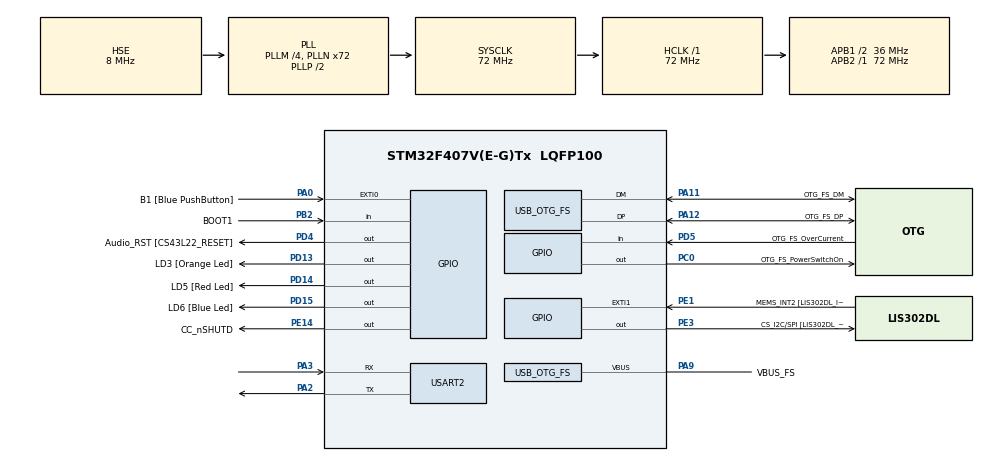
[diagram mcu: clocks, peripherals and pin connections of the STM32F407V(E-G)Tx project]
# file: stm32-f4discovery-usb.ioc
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Mcu.Family=STM32F4
PA11.GPIO_Speed=GPIO_SPEED_FREQ_LOW
PC3.GPIO_Mode=GPIO_MODE_AF_PP
PH0-OSC_IN.Signal=RCC_OSC_IN
RCC.CortexFreq_Value=72000000
PC10.GPIO_PuPd=GPIO_NOPULL
PB10.GPIO_Speed=GPIO_SPEED_FREQ_LOW
PB6.GPIO_Mode=GPIO_MODE_AF_OD
PB10.GPIO_PuPd=GPIO_NOPULL
PA10.GPIO_PuPd=GPIO_NOPULL
PD15.GPIO_Speed=GPIO_SPEED_FREQ_LOW
PC10.Signal=I2S3_CK
PC12.Signal=I2S3_SD
PA14.GPIO_Label=SWCLK
PA7.GPIO_Mode=GPIO_MODE_AF_PP
PC0.GPIO_Label=OTG_FS_PowerSwitchOn
PA11.Mode=Host_Only
PA6.GPIO_Label=SPI1_MISO [LIS302DL_SDO]
PB6.GPIO_Label=Audio_SCL [CS43L22_SCL]
PC10.GPIO_Speed=GPIO_SPEED_FREQ_LOW
PA11.GPIO_PuPd=GPIO_NOPULL
VP_USB_HOST_VS_USB_HOST_HID_FS.Mode=HID_FS
PC15-OSC32_OUT.GPIO_Label=PC15-OSC32_OUT
PC3.GPIO_Speed=GPIO_SPEED_FREQ_LOW
RCC.SYSCLKSource=RCC_SYSCLKSOURCE_PLLCLK
ProjectManager.StackSize=0x400
PA6.GPIO_Mode=GPIO_MODE_AF_PP
PD13.Signal=GPIO_Output
PD14.GPIO_Speed=GPIO_SPEED_FREQ_LOW
PA12.Signal=USB_OTG_FS_DP
RCC.HCLKFreq_Value=72000000
PD4.Signal=GPIO_Output
RCC.APB2TimFreq_Value=72000000
PB6.Signal=I2C1_SCL
PC7.Signal=I2S3_MCK
PC3.Signal=I2S2_SD
PE1.Signal=GPXTI1
USB_HOST0.BSP.ip=GPIO
RCC.AHBFreq_Value=72000000
PH0-OSC_IN.Mode=HSE-External-Oscillator
PH0-OSC_IN.GPIO_Label=PH0-OSC_IN
PA9.GPIO_Mode=GPIO_MODE_INPUT
RCC.HSE_VALUE=8000000
USB_OTG_FS.phy_itface=HCD_PHY_EMBEDDED
PA4.GPIO_PuPd=GPIO_NOPULL
PB2.Signal=GPIO_Input
PA4.GPIO_Speed=GPIO_SPEED_FREQ_LOW
PA6.GPIO_PuPd=GPIO_NOPULL
PA5.GPIO_PuPd=GPIO_NOPULL
USB_HOST.USBH_HandleTypeDef-HID_FS=hUsbHostFS
PA10.GPIO_Label=OTG_FS_ID
PC7.GPIO_Mode=GPIO_MODE_AF_PP
PD5.GPIO_Mode=GPIO_MODE_INPUT
PD14.GPIO_PuPd=GPIO_NOPULL
PB2.GPIO_PuPd=GPIO_NOPULL
PH1-OSC_OUT.Mode=HSE-External-Oscillator
USB_HOST0.BSP.i2caddr=0
PD13.GPIO_Label=LD3 [Orange Led]
Mcu.Package=LQFP100
PB9.Signal=I2C1_SDA
PA6.Signal=SPI1_MISO
USART2.VirtualMode=VM_ASYNC
PD12.Signal=USART3_RTS
PD5.GPIO_Label=OTG_FS_OverCurrent
NVIC.OTG_FS_IRQn=true\:0\:0\:false\:false\:true\:false\:true
PD15.GPIO_PuPd=GPIO_NOPULL
PA10.Signal=USB_OTG_FS_ID
PB9.GPIO_PuPd=GPIO_NOPULL
USB_OTG_FS.VirtualMode=Host_Only
PA10.GPIO_Speed=GPIO_SPEED_FREQ_LOW
USB_HOST0.BSP.name=Drive_VBUS_FS
PB9.GPIO_Speed=GPIO_SPEED_FREQ_LOW
RCC.APB1TimFreq_Value=72000000
PC14-OSC32_IN.GPIO_Label=PC14-OSC32_IN
PC12.GPIO_PuPd=GPIO_NOPULL
PA6.GPIO_Speed=GPIO_SPEED_FREQ_LOW
PC0.GPIO_PuPd=GPIO_NOPULL
PA12.GPIO_PuPd=GPIO_NOPULL
PA4.GPIO_Label=I2S3_WS [CS43L22_LRCK]
PD15.Signal=GPIO_Output
PA12.GPIO_Speed=GPIO_SPEED_FREQ_LOW
PA3.Signal=USART2_RX
PB3.GPIO_Label=SWO
PD15.GPIO_Label=LD6 [Blue Led]
PB9.GPIO_Label=Audio_SDA [CS43L22_SDA]
PC10.GPIO_Label=I2S3_SCK [CS43L22_SCLK]
PA9.GPIO_Label=VBUS_FS
PB6.GPIO_PuPd=GPIO_NOPULL
USB_HOST0.BSP.solution=PC0
USB_HOST.BSP.number=1
PA11.GPIO_Label=OTG_FS_DM
PE14.GPIO_Label=CC_nSHUTD
PE1.GPIO_PuPd=GPIO_NOPULL
PD9.Signal=USART3_RX
PD5.Signal=GPIO_Input
PC0.Signal=GPIO_Output
PE1.GPIO_ModeDefaultEXTI=GPIO_MODE_EVT_RISING
RCC.APB1CLKDivider=RCC_HCLK_DIV2
PC14-OSC32_IN.Signal=RCC_OSC32_IN
PA9.GPIO_PuPd=GPIO_NOPULL
NVIC.USART2_IRQn=true\:15\:0\:true\:false\:true\:true\:true
PA0-WKUP.GPIO_ModeDefaultEXTI=GPIO_MODE_EVT_RISING
PA12.GPIO_Label=OTG_FS_DP
PA0-WKUP.GPIO_Label=B1 [Blue PushButton]
PA0-WKUP.Signal=GPXTI0
PA10.GPIO_Mode=GPIO_MODE_AF_PP
USB_HOST0.BSP.STBoard=false
PA3.Mode=Asynchronous
PA13.Signal=SYS_JTMS-SWDIO
PC10.GPIO_Mode=GPIO_MODE_AF_PP
PD4.GPIO_PuPd=GPIO_NOPULL
PA9.Mode=Activate_VBUS
PC0.GPIO_Speed=GPIO_SPEED_FREQ_LOW
PB10.GPIO_Mode=GPIO_MODE_AF_PP
ProjectManager.TargetToolchain=Makefile
PB10.GPIO_Label=CLK_IN [MP45DT02_CLK]
PA9.Signal=USB_OTG_FS_VBUS
PC7.GPIO_PuPd=GPIO_NOPULL
RCC.LSE_VALUE=32768
PC15-OSC32_OUT.Signal=RCC_OSC32_OUT
PA7.GPIO_PuPd=GPIO_NOPULL
PB10.Signal=I2S2_CK
PA5.Signal=SPI1_SCK
board=STM32F4DISCOVERY
PD13.GPIO_Speed=GPIO_SPEED_FREQ_LOW
PC7.GPIO_Speed=GPIO_SPEED_FREQ_LOW
RCC.VCOOutputFreq_Value=144000000
PE1.GPIO_Label=MEMS_INT2 [LIS302DL_INT2]
USB_HOST.VirtualModeFS=Hid
PA7.GPIO_Speed=GPIO_SPEED_FREQ_LOW
PB9.GPIO_Mode=GPIO_MODE_AF_OD
PA12.GPIO_Mode=GPIO_MODE_AF_PP
PA4.GPIO_Mode=GPIO_MODE_AF_PP
RCC.APB2Freq_Value=72000000
USB_HOST0.BSP.api=Unknown
PB2.GPIO_Mode=GPIO_MODE_INPUT
PE14.Signal=GPIO_Output
PD4.GPIO_Label=Audio_RST [CS43L22_RESET]
PD4.GPIO_Speed=GPIO_SPEED_FREQ_LOW
PE3.GPIO_PuPd=GPIO_NOPULL
PH1-OSC_OUT.Signal=RCC_OSC_OUT
PD13.GPIO_PuPd=GPIO_NOPULL
PD5.GPIO_PuPd=GPIO_NOPULL
PD14.GPIO_Label=LD5 [Red Led]
PH1-OSC_OUT.GPIO_Label=PH1-OSC_OUT
Mcu.Name=STM32F407V(E-G)Tx
PA2.Signal=USART2_TX
PA13.GPIO_Label=SWDIO
PC7.GPIO_Label=I2S3_MCK [CS43L22_MCLK]
PD14.Signal=GPIO_Output
RCC.48MHZClocksFreq_Value=48000000
PB3.Signal=SYS_JTDO-SWO
PA4.Signal=I2S3_WS
RCC.SYSCLKFreq_VALUE=72000000
PC12.GPIO_Mode=GPIO_MODE_AF_PP
PA7.GPIO_Label=SPI1_MOSI [LIS302DL_SDA/SDI/SDO]
PA12.Mode=Host_Only
PA5.GPIO_Label=SPI1_SCK [LIS302DL_SCL/SPC]
PE3.GPIO_Speed=GPIO_SPEED_FREQ_LOW
PD11.Signal=USART3_CTS
PC12.GPIO_Label=I2S3_SD [CS43L22_SDIN]
PA11.Signal=USB_OTG_FS_DM
PA14.Signal=SYS_JTCK-SWCLK
PB2.GPIO_Label=BOOT1
ProjectManager.HeapSize=0x200
RCC.HSI_VALUE=16000000
PA5.GPIO_Speed=GPIO_SPEED_FREQ_LOW
RCC.PLLQ=3
NVIC.PriorityGroup=NVIC_PRIORITYGROUP_4
RCC.PLLM=4
RCC.PLLN=72
PE3.Signal=GPIO_Output
PA2.Mode=Asynchronous
PE3.GPIO_Label=CS_I2C/SPI [LIS302DL_CS_I2C/SPI]
PC3.GPIO_Label=PDM_OUT [MP45DT02_DOUT]
PA0-WKUP.GPIO_PuPd=GPIO_NOPULL
PA11.GPIO_Mode=GPIO_MODE_AF_PP
PB6.GPIO_Speed=GPIO_SPEED_FREQ_LOW
RCC.APB1Freq_Value=36000000
PA5.GPIO_Mode=GPIO_MODE_AF_PP
PC12.GPIO_Speed=GPIO_SPEED_FREQ_LOW
USB_HOST0.BSP.mode=Output
PC3.GPIO_PuPd=GPIO_NOPULL
PA7.Signal=SPI1_MOSI
USB_HOST0.BSP.instance=PC0

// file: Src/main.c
/* USER CODE BEGIN Header */
/**
  ******************************************************************************
  * @file           : main.c
  * @brief          : Main program body
  ******************************************************************************
  * @attention
  *
  * <h2><center>&copy; Copyright (c) 2020 STMicroelectronics.
  * All rights reserved.</center></h2>
  *
  * This software component is licensed by ST under BSD 3-Clause license,
  * the "License"; You may not use this file except in compliance with the
  * License. You may obtain a copy of the License at:
  *                        opensource.org/licenses/BSD-3-Clause
  *
  ******************************************************************************
  */
/* USER CODE END Header */

#include "main.h"
#include "usart.h"
#include "usb_host.h"
#include "gpio.h"

/* USER CODE BEGIN Includes */
#include "port.h"
/* USER CODE END Includes */

void SystemClock_Config(void);
void MX_USB_HOST_Process(void);

int main(void)
{

  /* MCU Configuration--------------------------------------------------------*/

  /* Reset of all peripherals, Initializes the Flash interface and the Systick. */
  HAL_Init();

  /* Configure the system clock */
  SystemClock_Config();

  /* Initialize all configured peripherals */
  MX_GPIO_Init();
  MX_USART2_UART_Init();
  MX_USB_HOST_Init();

  /* Infinite loop */
  /* USER CODE BEGIN WHILE */
  // jump to BTstack port
  port_main();
  while (1)
  {
    /* USER CODE END WHILE */
    MX_USB_HOST_Process();

  }
}

void SystemClock_Config(void)
{
  RCC_OscInitTypeDef RCC_OscInitStruct = {0};
  RCC_ClkInitTypeDef RCC_ClkInitStruct = {0};

  /** Configure the main internal regulator output voltage
  */
  __HAL_RCC_PWR_CLK_ENABLE();
  __HAL_PWR_VOLTAGESCALING_CONFIG(PWR_REGULATOR_VOLTAGE_SCALE1);
  /** Initializes the CPU, AHB and APB busses clocks
  */
  RCC_OscInitStruct.OscillatorType = RCC_OSCILLATORTYPE_HSE;
  RCC_OscInitStruct.HSEState = RCC_HSE_ON;
  RCC_OscInitStruct.PLL.PLLState = RCC_PLL_ON;
  RCC_OscInitStruct.PLL.PLLSource = RCC_PLLSOURCE_HSE;
  RCC_OscInitStruct.PLL.PLLM = 4;
  RCC_OscInitStruct.PLL.PLLN = 72;
  RCC_OscInitStruct.PLL.PLLP = RCC_PLLP_DIV2;
  RCC_OscInitStruct.PLL.PLLQ = 3;
  if (HAL_RCC_OscConfig(&RCC_OscInitStruct) != HAL_OK)
  {
    Error_Handler();
  }
  /** Initializes the CPU, AHB and APB busses clocks
  */
  RCC_ClkInitStruct.ClockType = RCC_CLOCKTYPE_HCLK|RCC_CLOCKTYPE_SYSCLK
                              |RCC_CLOCKTYPE_PCLK1|RCC_CLOCKTYPE_PCLK2;
  RCC_ClkInitStruct.SYSCLKSource = RCC_SYSCLKSOURCE_PLLCLK;
  RCC_ClkInitStruct.AHBCLKDivider = RCC_SYSCLK_DIV1;
  RCC_ClkInitStruct.APB1CLKDivider = RCC_HCLK_DIV2;
  RCC_ClkInitStruct.APB2CLKDivider = RCC_HCLK_DIV1;

  if (HAL_RCC_ClockConfig(&RCC_ClkInitStruct, FLASH_LATENCY_2) != HAL_OK)
  {
    Error_Handler();
  }
}

void Error_Handler(void)
{
}

/************************ (C) COPYRIGHT STMicroelectronics *****END OF FILE****/
